# psoc4100sp256kb register map
Vendor: Infineon Technologies; Series: PSOC4100Sp256KB; File version: 1.0
CPU: CM0PLUS r0p1, little endian, MPU, no FPU, VTOR, 2 interrupt priority bits, 29 interrupts
Registers are 32-bit, read-write, reset 0x0 unless marked. A register's access mark holds for its fields unless they carry their own. Offsets are from the block's base; [hi:lo] are bit positions; 'fields as' and 'values as' point back to an identical list.

## CTBM0 — Continuous Time Block Mini
Base 0x40300000
Same registers: CTBM1 0x40400000
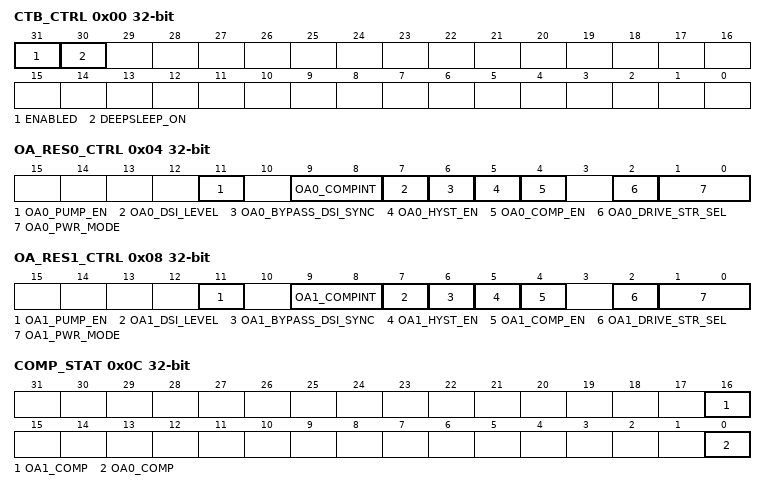
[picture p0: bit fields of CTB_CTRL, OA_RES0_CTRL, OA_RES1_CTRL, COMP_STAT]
0x00 CTB_CTRL — global CTB and power control
  [31] ENABLED — - 0: CTB IP disabled (put analog in power down, open all switches) - 1: CTB IP enabled
  [30] DEEPSLEEP_ON — - 0: CTB IP disabled off during DeepSleep power mode - 1: CTB IP remains enabled during DeepSleep power mode (if ENABLED=1)
0x04 OA_RES0_CTRL — Opamp0 and resistor0 control
  [11] OA0_PUMP_EN — Opamp0 pump enable
  [9:8] OA0_COMPINT — Opamp0 comparator edge detect for interrupt and pulse mode of DSI (trigger)
    0=DISABLE (Disabled, no interrupts will be detected); 1=RISING (Rising edge); 2=FALLING (Falling edge); 3=BOTH (Both rising and falling edges)
  [7] OA0_DSI_LEVEL — Opamp0 comparator DSI (trigger) out level : 0=pulse, each time an edge is detected (see OA0_COMPINT) a pulse is sent out on DSI 1=level, DSI output is a synchronized version of the comparator output
  [6] OA0_BYPASS_DSI_SYNC — Opamp0 bypass comparator output synchronization for DSI (trigger) output: 0=synchronize (level or pulse), 1=bypass (output async)
  [5] OA0_HYST_EN — Opamp0 hysteresis enable (10mV)
  [4] OA0_COMP_EN — Opamp0 comparator enable
  [2] OA0_DRIVE_STR_SEL — Opamp0 output strenght select 0=1x, 1=10x
  [1:0] OA0_PWR_MODE — Opamp0 power level
    0=OFF; 1=LOW (Low compensation setting (smallest cap, highest GBW). For gain=10: PM=60deg @ Cload=50pF for the output to pin driver and 10pF for the internal only driver); 2=MEDIUM (Medium compensation setting. For gain=4: PM=60deg @ Cload=50pF for the output to pin driver and 10pF for the internal only driver.); 3=HIGH (Highest compensation (largest cap, lowest GBW). For gain=1: PM=60deg @ Cload=50pF for the output to pin driver and 10pF for the internal only driver)
0x08 OA_RES1_CTRL — Opamp1 and resistor1 control
  [11] OA1_PUMP_EN — Opamp1 pump enable
  [9:8] OA1_COMPINT — Opamp1 comparator edge detect for interrupt and pulse mode of DSI (trigger)
    values as OA_RES0_CTRL.OA0_COMPINT
  [7] OA1_DSI_LEVEL — Opamp1 comparator DSI (trigger) out level : 0=pulse, each time an edge is detected (see OA1_COMPINT) a pulse is sent out on DSI 1=level, DSI output is a synchronized version of the comparator output
  [6] OA1_BYPASS_DSI_SYNC — Opamp1 bypass comparator output synchronization for DSI output: 0=synchronize, 1=bypass
  [5] OA1_HYST_EN — Opamp1 hysteresis enable (10mV)
  [4] OA1_COMP_EN — Opamp1 comparator enable
  [2] OA1_DRIVE_STR_SEL — Opamp1 output strenght select 0=1x, 1=10x
  [1:0] OA1_PWR_MODE — Opamp1 power level: see description of OA0_PWR_MODE
0x0C COMP_STAT ro — Comparator status
  [16] OA1_COMP — Opamp1 current comparator status
  [0] OA0_COMP — Opamp0 current comparator status
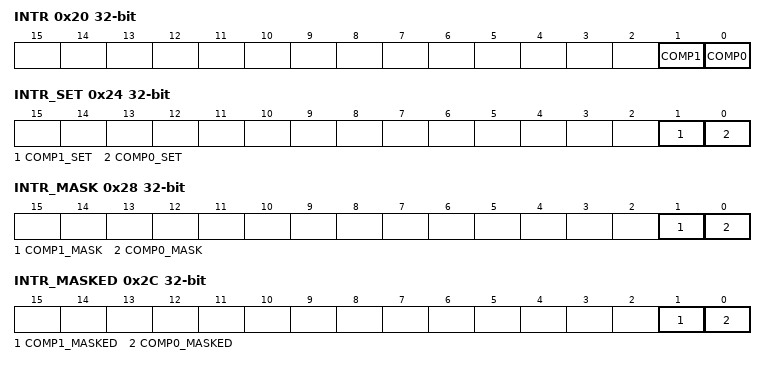
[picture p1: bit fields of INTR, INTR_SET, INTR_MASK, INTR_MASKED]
0x20 INTR — Interrupt request register
  [1] COMP1 write-1-clears — Comparator 1 Interrupt: hardware sets this interrupt when comparator 1 triggers. Write with '1' to clear bit.
  [0] COMP0 write-1-clears — Comparator 0 Interrupt: hardware sets this interrupt when comparator 0 triggers. Write with '1' to clear bit.
0x24 INTR_SET — Interrupt request set register
  [1] COMP1_SET write-1-sets — Write with '1' to set corresponding bit in interrupt request register.
  [0] COMP0_SET write-1-sets — Write with '1' to set corresponding bit in interrupt request register.
0x28 INTR_MASK — Interrupt request mask
  [1] COMP1_MASK — Mask bit for corresponding bit in interrupt request register.
  [0] COMP0_MASK — Mask bit for corresponding bit in interrupt request register.
0x2C INTR_MASKED ro — Interrupt request masked
  [1] COMP1_MASKED — Logical and of corresponding request and mask bits.
  [0] COMP0_MASKED — Logical and of corresponding request and mask bits.
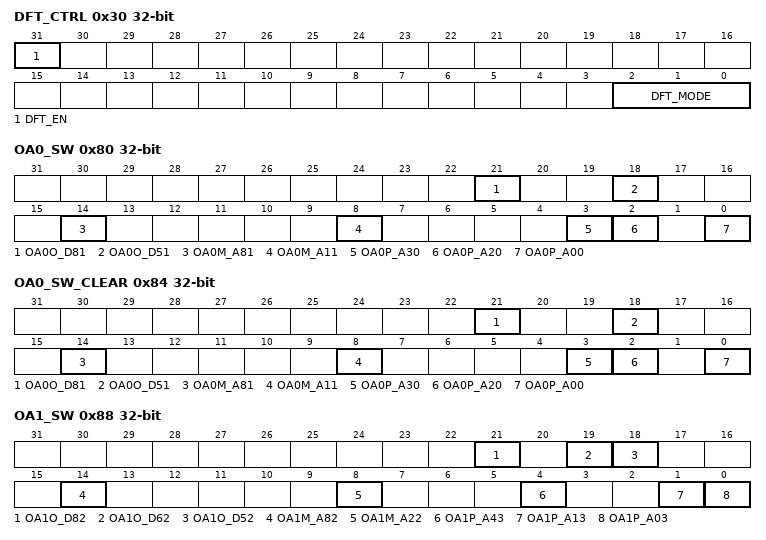
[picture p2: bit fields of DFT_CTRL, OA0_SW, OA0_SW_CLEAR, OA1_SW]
0x30 DFT_CTRL — Was 'Analog DfT controls', now used as Risk Mitigation bits (RMP)
  [31] DFT_EN — this bit is combined with the 3 bits 2:0, to form RMP[3:0]
  [2:0] DFT_MODE — this bit is combined with bit 31, to form RMP[3:0], it must always be written with '3' for correct operation.
0x80 OA0_SW — Opamp0 switch control
  [21] OA0O_D81 write-1-sets — Opamp0 output switch to short 1x with 10x drive
  [18] OA0O_D51 write-1-sets — Opamp0 output sarbus0 (ctbbus2 in CTB)
  [14] OA0M_A81 write-1-sets — Opamp0 negative terminal Opamp0 output
  [8] OA0M_A11 write-1-sets — Opamp0 negative terminal P1
  [3] OA0P_A30 write-1-sets — Opamp0 positive terminal ctbbus0
  [2] OA0P_A20 write-1-sets — Opamp0 positive terminal P0
  [0] OA0P_A00 write-1-sets — Opamp0 positive terminal amuxbusa
0x84 OA0_SW_CLEAR — Opamp0 switch control clear
  [21] OA0O_D81 write-1-clears — see corresponding bit in OA0_SW
  [18] OA0O_D51 write-1-clears — see corresponding bit in OA0_SW
  [14] OA0M_A81 write-1-clears — see corresponding bit in OA0_SW
  [8] OA0M_A11 write-1-clears — see corresponding bit in OA0_SW
  [3] OA0P_A30 write-1-clears — see corresponding bit in OA0_SW
  [2] OA0P_A20 write-1-clears — see corresponding bit in OA0_SW
  [0] OA0P_A00 write-1-clears — see corresponding bit in OA0_SW
0x88 OA1_SW — Opamp1 switch control
  [21] OA1O_D82 write-1-sets — Opamp1 output switch to short 1x with 10x drive
  [19] OA1O_D62 write-1-sets — Opamp1 output sarbus1 (ctbbus3 in CTB)
  [18] OA1O_D52 write-1-sets — Opamp1 output sarbus0 (ctbbus2 in CTB)
  [14] OA1M_A82 write-1-sets — Opamp1 negative terminal Opamp1 output
  [8] OA1M_A22 write-1-sets — Opamp1 negative terminal P4
  [4] OA1P_A43 write-1-sets — Opamp1 positive terminal ctbbus1
  [1] OA1P_A13 write-1-sets — Opamp1 positive terminal P5
  [0] OA1P_A03 write-1-sets — Opamp1 positive terminal amuxbusb
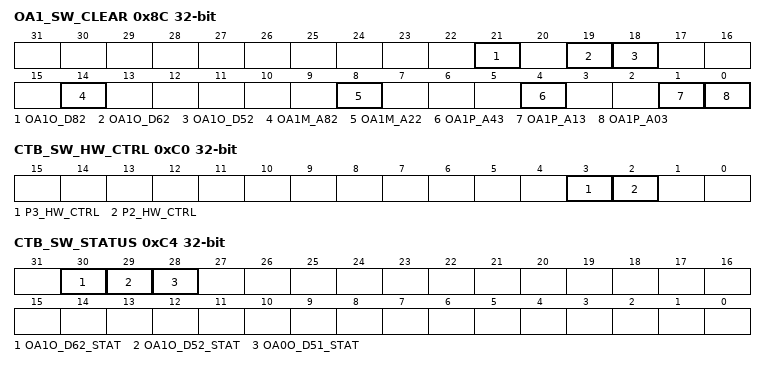
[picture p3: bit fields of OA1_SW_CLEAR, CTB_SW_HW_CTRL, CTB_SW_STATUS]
0x8C OA1_SW_CLEAR — Opamp1 switch control clear
  [21] OA1O_D82 write-1-clears — see corresponding bit in OA1_SW
  [19] OA1O_D62 write-1-clears — see corresponding bit in OA1_SW
  [18] OA1O_D52 write-1-clears — see corresponding bit in OA1_SW
  [14] OA1M_A82 write-1-clears — see corresponding bit in OA1_SW
  [8] OA1M_A22 write-1-clears — see corresponding bit in OA1_SW
  [4] OA1P_A43 write-1-clears — see corresponding bit in OA1_SW
  [1] OA1P_A13 write-1-clears — see corresponding bit in OA1_SW
  [0] OA1P_A03 write-1-clears — see corresponding bit in OA1_SW
0xC0 CTB_SW_HW_CTRL — CTB bus switch control
  [3] P3_HW_CTRL — for P33, D52, D62 (dsi_out[3])
  [2] P2_HW_CTRL — for P22, D51 (dsi_out[2])
0xC4 CTB_SW_STATUS ro — CTB bus switch control status
  [30] OA1O_D62_STAT — see OA1O_D62 bit in OA1_SW
  [29] OA1O_D52_STAT — see OA1O_D52 bit in OA1_SW
  [28] OA0O_D51_STAT — see OA0O_D51 bit in OA0_SW
0xF00 OA0_OFFSET_TRIM — Opamp0 trim control
  [5:0] OA0_OFFSET_TRIM — Opamp0 offset trim
0xF04 OA0_SLOPE_OFFSET_TRIM — Opamp0 trim control
  [5:0] OA0_SLOPE_OFFSET_TRIM — Opamp0 slope offset drift trim
0xF08 OA0_COMP_TRIM — Opamp0 trim control
  [1:0] OA0_COMP_TRIM — Opamp 0 Compensation Capacitor Trim
0xF0C OA1_OFFSET_TRIM — Opamp1 trim control
  [5:0] OA1_OFFSET_TRIM — Opamp1 offset trim
0xF10 OA1_SLOPE_OFFSET_TRIM — Opamp1 trim control
  [5:0] OA1_SLOPE_OFFSET_TRIM — Opamp1 slope offset drift trim
0xF14 OA1_COMP_TRIM — Opamp1 trim control
  [1:0] OA1_COMP_TRIM — Opamp 1 Compensation Capacitor Trim
